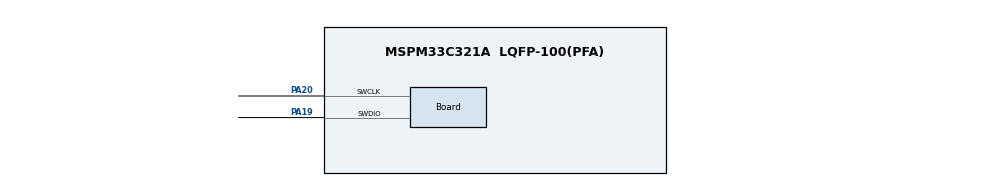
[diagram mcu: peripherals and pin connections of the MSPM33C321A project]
//@cliArgs --device "MSPM33C321A" --package "LQFP-100(PFA)" --part "Default"
//@v2CliArgs --device "MSPM33C321A" --package "LQFP-100(PFA)"
// @cliArgs --board /ti/boards/LP_MSPM33C321A --rtos nortos


/**
 * Import the modules used in this configuration.
 */
const SYSCTL = scripting.addModule("/ti/driverlib/SYSCTL");


/**
 * Write custom configuration values to the imported modules.
 */
SYSCTL.forceDefaultClkConfig = true;
SYSCTL.peripheral.$assign    = "SYSCTL";

const Board                       = scripting.addModule("/ti/driverlib/Board", {}, false);
Board.peripheral.$assign          = "DEBUGSS";
Board.peripheral.swclkPin.$assign = "PA20";
Board.peripheral.swdioPin.$assign = "PA19";

const ProjectConfig              = scripting.addModule("/ti/project_config/ProjectConfig", {}, false);
ProjectConfig.migrationCondition = true;

ProjectConfig.genLinker  = true;
ProjectConfig.genStartup = false;
ProjectConfig.genOpts    = true;
ProjectConfig.genLibs    = true;
